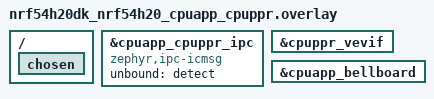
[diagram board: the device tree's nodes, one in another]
/*
 * Copyright (c) 2024 Nordic Semiconductor ASA
 * SPDX-License-Identifier: Apache-2.0
 */

/* Replace default ipc0 instance */
/delete-node/ &ipc0;

ipc0: &cpuapp_cpuppr_ipc {
	compatible = "zephyr,ipc-icmsg";
	status = "okay";
	/delete-property/ tx-blocks;
	/delete-property/ rx-blocks;
	unbound = "detect";
};

&cpuppr_vevif {
	status = "okay";
};

&cpuapp_bellboard {
	status = "okay";
};

/ {
	chosen {
		/delete-property/ zephyr,bt-hci;
	};
};
